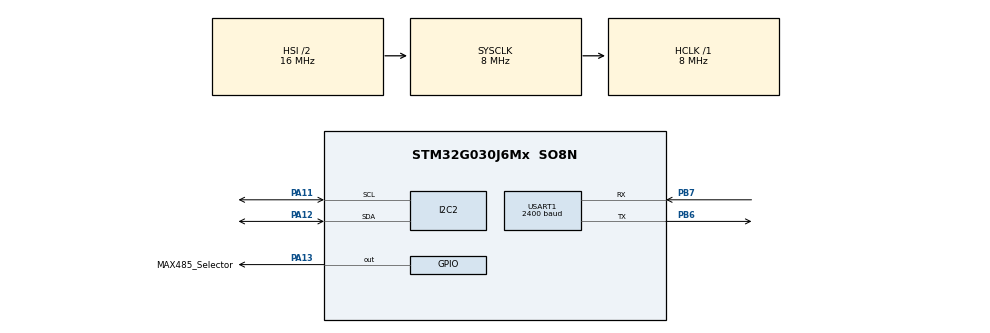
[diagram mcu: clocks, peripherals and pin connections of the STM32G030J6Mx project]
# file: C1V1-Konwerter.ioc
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ADC1.Channel-0\#ChannelRegularConversion=ADC_CHANNEL_TEMPSENSOR
ADC1.ChannelTS=ADC_CHANNEL_TEMPSENSOR
ADC1.NbrOfConversionFlag=1
ADC1.Rank-0\#ChannelRegularConversion=1
ADC1.SamplingTime-0\#ChannelRegularConversion=ADC_SAMPLINGTIME_COMMON_1
ADC1.SamplingTimeCommon1=ADC_SAMPLETIME_160CYCLES_5
ADC1.SamplingTimeCommon2=ADC_SAMPLETIME_160CYCLES_5
ADC1.SelectedChannel=ADC_CHANNEL_TEMPSENSOR
ADC1.master=1
Dma.Request0=USART1_RX
Dma.USART1_RX.0.Direction=DMA_PERIPH_TO_MEMORY
Dma.USART1_RX.0.EventEnable=DISABLE
Dma.USART1_RX.0.Instance=DMA1_Channel1
Dma.USART1_RX.0.MemDataAlignment=DMA_MDATAALIGN_BYTE
Dma.USART1_RX.0.MemInc=DMA_MINC_ENABLE
Dma.USART1_RX.0.Mode=DMA_NORMAL
Dma.USART1_RX.0.PeriphDataAlignment=DMA_PDATAALIGN_BYTE
Dma.USART1_RX.0.PeriphInc=DMA_PINC_DISABLE
Dma.USART1_RX.0.Polarity=HAL_DMAMUX_REQ_GEN_RISING
Dma.USART1_RX.0.Priority=DMA_PRIORITY_LOW
Dma.USART1_RX.0.RequestNumber=1
Dma.USART1_RX.0.SignalID=NONE
Dma.USART1_RX.0.SyncEnable=DISABLE
Dma.USART1_RX.0.SyncPolarity=HAL_DMAMUX_SYNC_NO_EVENT
Dma.USART1_RX.0.SyncRequestNumber=1
Dma.USART1_RX.0.SyncSignalID=NONE
I2C2.Timing=0x2000090E
Mcu.Family=STM32G0
Mcu.Name=STM32G030J6Mx
Mcu.Package=SO8N
NRST__PA0__PA1__PA2.StandardMode=true
NVIC.DMA1_Channel1_IRQn=true\:0\:0\:false\:true\:true\:2\:false\:true\:true
NVIC.USART1_IRQn=true\:0\:0\:false\:true\:true\:3\:true\:true\:true
PA11\ [PA9].Mode=I2C
PA11\ [PA9].Signal=I2C2_SCL
PA12\ [PA10].Mode=I2C
PA12\ [PA10].Signal=I2C2_SDA
PA13.GPIO_Label=MAX485_Selector
PA13.GPIO_Speed=GPIO_SPEED_FREQ_VERY_HIGH
PA13.Signal=GPIO_Output
PA14-BOOT0__PA15__PB5__PB6.StandardMode=true
PB0__PB1__PA8__PA11\ [PA9].StandardMode=true
PB6.Mode=Asynchronous
PB6.Signal=USART1_TX
PB7.Mode=Asynchronous
PB7.Signal=USART1_RX
PC14-OSC32_IN\ (PC14)__PB7__PB8__PB9.StandardMode=true
ProjectManager.HeapSize=0x200
ProjectManager.StackSize=0xcff
ProjectManager.TargetToolchain=STM32CubeIDE
RCC.ADCFreq_Value=8000000
RCC.AHBFreq_Value=8000000
RCC.CortexFreq_Value=8000000
RCC.EXTERNAL_CLOCK_VALUE=12288000
RCC.HCLKFreq_Value=8000000
RCC.HSE_VALUE=8000000
RCC.HSISYSCLKDivider=RCC_HSI_DIV2
RCC.HSI_VALUE=16000000
RCC.LSE_VALUE=32768
RCC.SYSCLKFreq_VALUE=8000000
RCC.USART1CLockSelection=RCC_USART1CLKSOURCE_SYSCLK
RCC.VCOOutputFreq_Value=128000000
TIM17.Prescaler=15
USART1.BaudRate=2400
USART1.OverrunDisableParam=ADVFEATURE_OVERRUN_DISABLE
USART1.VirtualMode-Asynchronous=VM_ASYNC
VP_ADC1_TempSens_Input.Mode=IN-TempSens
VP_TIM17_VS_ClockSourceINT.Mode=Enable_Timer
board=custom

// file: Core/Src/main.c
/* USER CODE BEGIN Header */
/**
 ******************************************************************************
 * @file           : main.c
 * @brief          : Main program body
 ******************************************************************************
 * @attention
 *
 * Copyright (c) 2022 STMicroelectronics.
 * All rights reserved.
 *
 * This software is licensed under terms that can be found in the LICENSE file
 * in the root directory of this software component.
 * If no LICENSE file comes with this software, it is provided AS-IS.
 *
 ******************************************************************************
 */
/* USER CODE END Header */
#include "main.h"
#include "adc.h"
#include "dma.h"
#include "i2c.h"
#include "tim.h"
#include "usart.h"
#include "gpio.h"

/* USER CODE BEGIN Includes */
#include "SM.h"
#include "bh1750.h"
/* USER CODE END Includes */

void SystemClock_Config(void);
static void MX_NVIC_Init(void);

int main(void)
{

  /* MCU Configuration--------------------------------------------------------*/

  /* Reset of all peripherals, Initializes the Flash interface and the Systick. */
  HAL_Init();

  /* Configure the system clock */
  SystemClock_Config();

  /* Initialize all configured peripherals */
  MX_GPIO_Init();
  MX_DMA_Init();
  MX_I2C2_Init();
  MX_TIM17_Init();
  MX_ADC1_Init();
  MX_USART1_UART_Init();

  /* Initialize interrupts */
  MX_NVIC_Init();
  /* USER CODE BEGIN 2 */
   HAL_TIM_Base_Start(&htim17);
   // HAL_Delay(5000);

  /* USER CODE END 2 */

  /* Infinite loop */
  /* USER CODE BEGIN WHILE */
   while(1)
   {
      SM_MainFunction();
    /* USER CODE END WHILE */

   }
}

void SystemClock_Config(void)
{
  RCC_OscInitTypeDef RCC_OscInitStruct = {0};
  RCC_ClkInitTypeDef RCC_ClkInitStruct = {0};

  /** Configure the main internal regulator output voltage
  */
  HAL_PWREx_ControlVoltageScaling(PWR_REGULATOR_VOLTAGE_SCALE1);

  /** Initializes the RCC Oscillators according to the specified parameters
  * in the RCC_OscInitTypeDef structure.
  */
  RCC_OscInitStruct.OscillatorType = RCC_OSCILLATORTYPE_HSI;
  RCC_OscInitStruct.HSIState = RCC_HSI_ON;
  RCC_OscInitStruct.HSIDiv = RCC_HSI_DIV2;
  RCC_OscInitStruct.HSICalibrationValue = RCC_HSICALIBRATION_DEFAULT;
  RCC_OscInitStruct.PLL.PLLState = RCC_PLL_NONE;
  if (HAL_RCC_OscConfig(&RCC_OscInitStruct) != HAL_OK)
  {
    Error_Handler();
  }

  /** Initializes the CPU, AHB and APB buses clocks
  */
  RCC_ClkInitStruct.ClockType = RCC_CLOCKTYPE_HCLK|RCC_CLOCKTYPE_SYSCLK
                              |RCC_CLOCKTYPE_PCLK1;
  RCC_ClkInitStruct.SYSCLKSource = RCC_SYSCLKSOURCE_HSI;
  RCC_ClkInitStruct.AHBCLKDivider = RCC_SYSCLK_DIV1;
  RCC_ClkInitStruct.APB1CLKDivider = RCC_HCLK_DIV1;

  if (HAL_RCC_ClockConfig(&RCC_ClkInitStruct, FLASH_LATENCY_0) != HAL_OK)
  {
    Error_Handler();
  }
}

/**
  * @brief NVIC Configuration.
  * @retval None
  */
static void MX_NVIC_Init(void)
{
  /* DMA1_Channel1_IRQn interrupt configuration */
  HAL_NVIC_SetPriority(DMA1_Channel1_IRQn, 0, 0);
  HAL_NVIC_EnableIRQ(DMA1_Channel1_IRQn);
  /* USART1_IRQn interrupt configuration */
  HAL_NVIC_SetPriority(USART1_IRQn, 0, 0);
  HAL_NVIC_EnableIRQ(USART1_IRQn);
}

void Error_Handler(void)
{
   __disable_irq();
   while(1)
   {
   }
}
